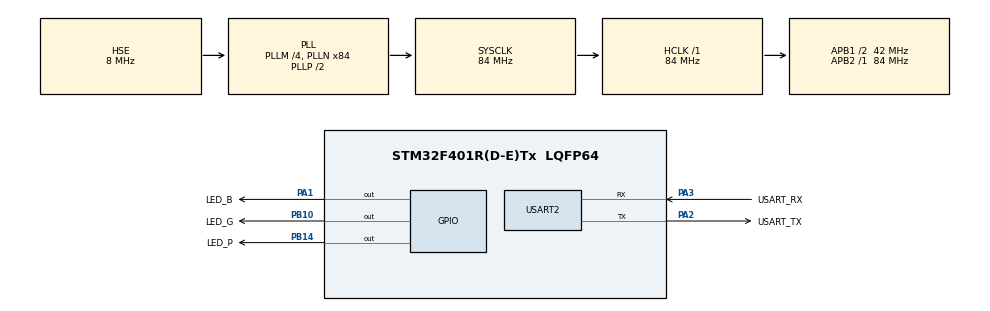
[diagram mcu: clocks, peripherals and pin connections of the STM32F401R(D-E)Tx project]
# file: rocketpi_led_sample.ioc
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FREERTOS.Tasks01=defaultTask,24,128,StartDefaultTask,Default,NULL,Dynamic,NULL,NULL;LEDP_TASK,8,128,ledp_task,Default,NULL,Dynamic,NULL,NULL;LEDG_TASK,8,128,ledg_task,Default,NULL,Dynamic,NULL,NULL;LEDB_TASK,8,128,ledb_task,Default,NULL,Dynamic,NULL,NULL
Mcu.Family=STM32F4
Mcu.Name=STM32F401R(D-E)Tx
Mcu.Package=LQFP64
NVIC.PriorityGroup=NVIC_PRIORITYGROUP_4
NVIC.TIM1_UP_TIM10_IRQn=true\:15\:0\:false\:false\:true\:false\:false\:true\:true
NVIC.TimeBase=TIM1_UP_TIM10_IRQn
NVIC.TimeBaseIP=TIM10
PA1.GPIO_Label=LED_B
PA1.Signal=GPIO_Output
PA13.GPIO_Label=TMS
PA13.Mode=Serial_Wire
PA13.Signal=SYS_JTMS-SWDIO
PA14.GPIO_Label=TCK
PA14.Mode=Serial_Wire
PA14.Signal=SYS_JTCK-SWCLK
PA2.GPIO_Label=USART_TX
PA2.GPIO_Mode=GPIO_MODE_AF_PP
PA2.GPIO_PuPd=GPIO_NOPULL
PA2.GPIO_Speed=GPIO_SPEED_FREQ_LOW
PA2.Mode=Asynchronous
PA2.Signal=USART2_TX
PA3.GPIO_Label=USART_RX
PA3.GPIO_Mode=GPIO_MODE_AF_PP
PA3.GPIO_PuPd=GPIO_NOPULL
PA3.GPIO_Speed=GPIO_SPEED_FREQ_LOW
PA3.Mode=Asynchronous
PA3.Signal=USART2_RX
PB10.GPIO_Label=LED_G
PB10.Signal=GPIO_Output
PB14.GPIO_Label=LED_P
PB14.Signal=GPIO_Output
PH0\ -\ OSC_IN.Mode=HSE-External-Oscillator
PH0\ -\ OSC_IN.Signal=RCC_OSC_IN
PH1\ -\ OSC_OUT.Mode=HSE-External-Oscillator
PH1\ -\ OSC_OUT.Signal=RCC_OSC_OUT
ProjectManager.HeapSize=0x800
ProjectManager.StackSize=0x800
ProjectManager.TargetToolchain=MDK-ARM V5.27
RCC.48MHZClocksFreq_Value=24000000
RCC.AHBFreq_Value=84000000
RCC.APB1CLKDivider=RCC_HCLK_DIV2
RCC.APB1Freq_Value=42000000
RCC.APB1TimFreq_Value=84000000
RCC.APB2Freq_Value=84000000
RCC.APB2TimFreq_Value=84000000
RCC.CortexFreq_Value=84000000
RCC.HCLKFreq_Value=84000000
RCC.HSE_VALUE=8000000
RCC.HSI_VALUE=16000000
RCC.LSE_VALUE=32768
RCC.PLLM=4
RCC.PLLN=84
RCC.PLLQ=7
RCC.PLLSourceVirtual=RCC_PLLSOURCE_HSE
RCC.SYSCLKFreq_VALUE=84000000
RCC.SYSCLKSource=RCC_SYSCLKSOURCE_PLLCLK
RCC.VCOOutputFreq_Value=168000000
USART2.VirtualMode=VM_ASYNC
VP_FREERTOS_VS_CMSIS_V2.Mode=CMSIS_V2
VP_SYS_VS_tim10.Mode=TIM10
board=NUCLEO-F401RE

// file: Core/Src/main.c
/* USER CODE BEGIN Header */
/**
  ******************************************************************************
  * @file           : main.c
  * @brief          : Main program body
  ******************************************************************************
  * @attention
  *
  * Copyright (c) 2025 STMicroelectronics.
  * All rights reserved.
  *
  * This software is licensed under terms that can be found in the LICENSE file
  * in the root directory of this software component.
  * If no LICENSE file comes with this software, it is provided AS-IS.
  *
  ******************************************************************************
  */
/* USER CODE END Header */
#include "main.h"
#include "cmsis_os.h"
#include "usart.h"
#include "gpio.h"

/* USER CODE BEGIN Includes */
#include <stdio.h>
/* USER CODE END Includes */

void SystemClock_Config(void);
void MX_FREERTOS_Init(void);

int main(void)
{

  /* MCU Configuration--------------------------------------------------------*/

  /* Reset of all peripherals, Initializes the Flash interface and the Systick. */
  HAL_Init();

  /* Configure the system clock */
  SystemClock_Config();

  /* Initialize all configured peripherals */
  MX_GPIO_Init();
  MX_USART2_UART_Init();

  /* Init scheduler */
  osKernelInitialize();

  /* Call init function for freertos objects (in cmsis_os2.c) */
  MX_FREERTOS_Init();

  /* Start scheduler */
  osKernelStart();

  /* We should never get here as control is now taken by the scheduler */

  /* Infinite loop */
  while (1)
  {

  }
}

void SystemClock_Config(void)
{
  RCC_OscInitTypeDef RCC_OscInitStruct = {0};
  RCC_ClkInitTypeDef RCC_ClkInitStruct = {0};

  /** Configure the main internal regulator output voltage
  */
  __HAL_RCC_PWR_CLK_ENABLE();
  __HAL_PWR_VOLTAGESCALING_CONFIG(PWR_REGULATOR_VOLTAGE_SCALE2);

  /** Initializes the RCC Oscillators according to the specified parameters
  * in the RCC_OscInitTypeDef structure.
  */
  RCC_OscInitStruct.OscillatorType = RCC_OSCILLATORTYPE_HSE;
  RCC_OscInitStruct.HSEState = RCC_HSE_ON;
  RCC_OscInitStruct.PLL.PLLState = RCC_PLL_ON;
  RCC_OscInitStruct.PLL.PLLSource = RCC_PLLSOURCE_HSE;
  RCC_OscInitStruct.PLL.PLLM = 4;
  RCC_OscInitStruct.PLL.PLLN = 84;
  RCC_OscInitStruct.PLL.PLLP = RCC_PLLP_DIV2;
  RCC_OscInitStruct.PLL.PLLQ = 7;
  if (HAL_RCC_OscConfig(&RCC_OscInitStruct) != HAL_OK)
  {
    Error_Handler();
  }

  /** Initializes the CPU, AHB and APB buses clocks
  */
  RCC_ClkInitStruct.ClockType = RCC_CLOCKTYPE_HCLK|RCC_CLOCKTYPE_SYSCLK
                              |RCC_CLOCKTYPE_PCLK1|RCC_CLOCKTYPE_PCLK2;
  RCC_ClkInitStruct.SYSCLKSource = RCC_SYSCLKSOURCE_PLLCLK;
  RCC_ClkInitStruct.AHBCLKDivider = RCC_SYSCLK_DIV1;
  RCC_ClkInitStruct.APB1CLKDivider = RCC_HCLK_DIV2;
  RCC_ClkInitStruct.APB2CLKDivider = RCC_HCLK_DIV1;

  if (HAL_RCC_ClockConfig(&RCC_ClkInitStruct, FLASH_LATENCY_2) != HAL_OK)
  {
    Error_Handler();
  }
}

void HAL_TIM_PeriodElapsedCallback(TIM_HandleTypeDef *htim)
{
  if (htim->Instance == TIM10)
  {
    HAL_IncTick();
  }
}

void Error_Handler(void)
{
  __disable_irq();
  while (1)
  {
  }
}

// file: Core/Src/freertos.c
/* USER CODE BEGIN Header */
/**
  ******************************************************************************
  * File Name          : freertos.c
  * Description        : Code for freertos applications
  ******************************************************************************
  * @attention
  *
  * Copyright (c) 2025 STMicroelectronics.
  * All rights reserved.
  *
  * This software is licensed under terms that can be found in the LICENSE file
  * in the root directory of this software component.
  * If no LICENSE file comes with this software, it is provided AS-IS.
  *
  ******************************************************************************
  */
/* USER CODE END Header */

#include "FreeRTOS.h"
#include "task.h"
#include "main.h"
#include "cmsis_os.h"

/* Definitions for defaultTask */
osThreadId_t defaultTaskHandle;
const osThreadAttr_t defaultTask_attributes = {
  .name = "defaultTask",
  .stack_size = 128 * 4,
  .priority = (osPriority_t) osPriorityNormal,
};
/* Definitions for LEDP_TASK */
osThreadId_t LEDP_TASKHandle;
const osThreadAttr_t LEDP_TASK_attributes = {
  .name = "LEDP_TASK",
  .stack_size = 128 * 4,
  .priority = (osPriority_t) osPriorityLow,
};
/* Definitions for LEDG_TASK */
osThreadId_t LEDG_TASKHandle;
const osThreadAttr_t LEDG_TASK_attributes = {
  .name = "LEDG_TASK",
  .stack_size = 128 * 4,
  .priority = (osPriority_t) osPriorityLow,
};
/* Definitions for LEDB_TASK */
osThreadId_t LEDB_TASKHandle;
const osThreadAttr_t LEDB_TASK_attributes = {
  .name = "LEDB_TASK",
  .stack_size = 128 * 4,
  .priority = (osPriority_t) osPriorityLow,
};

void StartDefaultTask(void *argument);
void ledp_task(void *argument);
void ledg_task(void *argument);
void ledb_task(void *argument);

void MX_FREERTOS_Init(void); /* (MISRA C 2004 rule 8.1) */

void MX_FREERTOS_Init(void) {

  /* Create the thread(s) */
  /* creation of defaultTask */
  defaultTaskHandle = osThreadNew(StartDefaultTask, NULL, &defaultTask_attributes);

  /* creation of LEDP_TASK */
  LEDP_TASKHandle = osThreadNew(ledp_task, NULL, &LEDP_TASK_attributes);

  /* creation of LEDG_TASK */
  LEDG_TASKHandle = osThreadNew(ledg_task, NULL, &LEDG_TASK_attributes);

  /* creation of LEDB_TASK */
  LEDB_TASKHandle = osThreadNew(ledb_task, NULL, &LEDB_TASK_attributes);

}

void StartDefaultTask(void *argument)
{
  for(;;)
  {
    osDelay(1);
  }
}

void ledp_task(void *argument)
{
  /* USER CODE BEGIN ledp_task */
  /* Infinite loop */
  for(;;)
  {
		HAL_GPIO_TogglePin(LED_P_GPIO_Port,LED_P_Pin);
    osDelay(500);
  }
  /* USER CODE END ledp_task */
}

void ledg_task(void *argument)
{
  /* USER CODE BEGIN ledg_task */
  /* Infinite loop */
  for(;;)
  {
		HAL_GPIO_TogglePin(LED_G_GPIO_Port,LED_G_Pin);
    osDelay(500);
  }
  /* USER CODE END ledg_task */
}

void ledb_task(void *argument)
{
  /* USER CODE BEGIN ledb_task */
  /* Infinite loop */
  for(;;)
  {
		HAL_GPIO_TogglePin(LED_B_GPIO_Port,LED_B_Pin);
    osDelay(500);
  }
  /* USER CODE END ledb_task */
}
